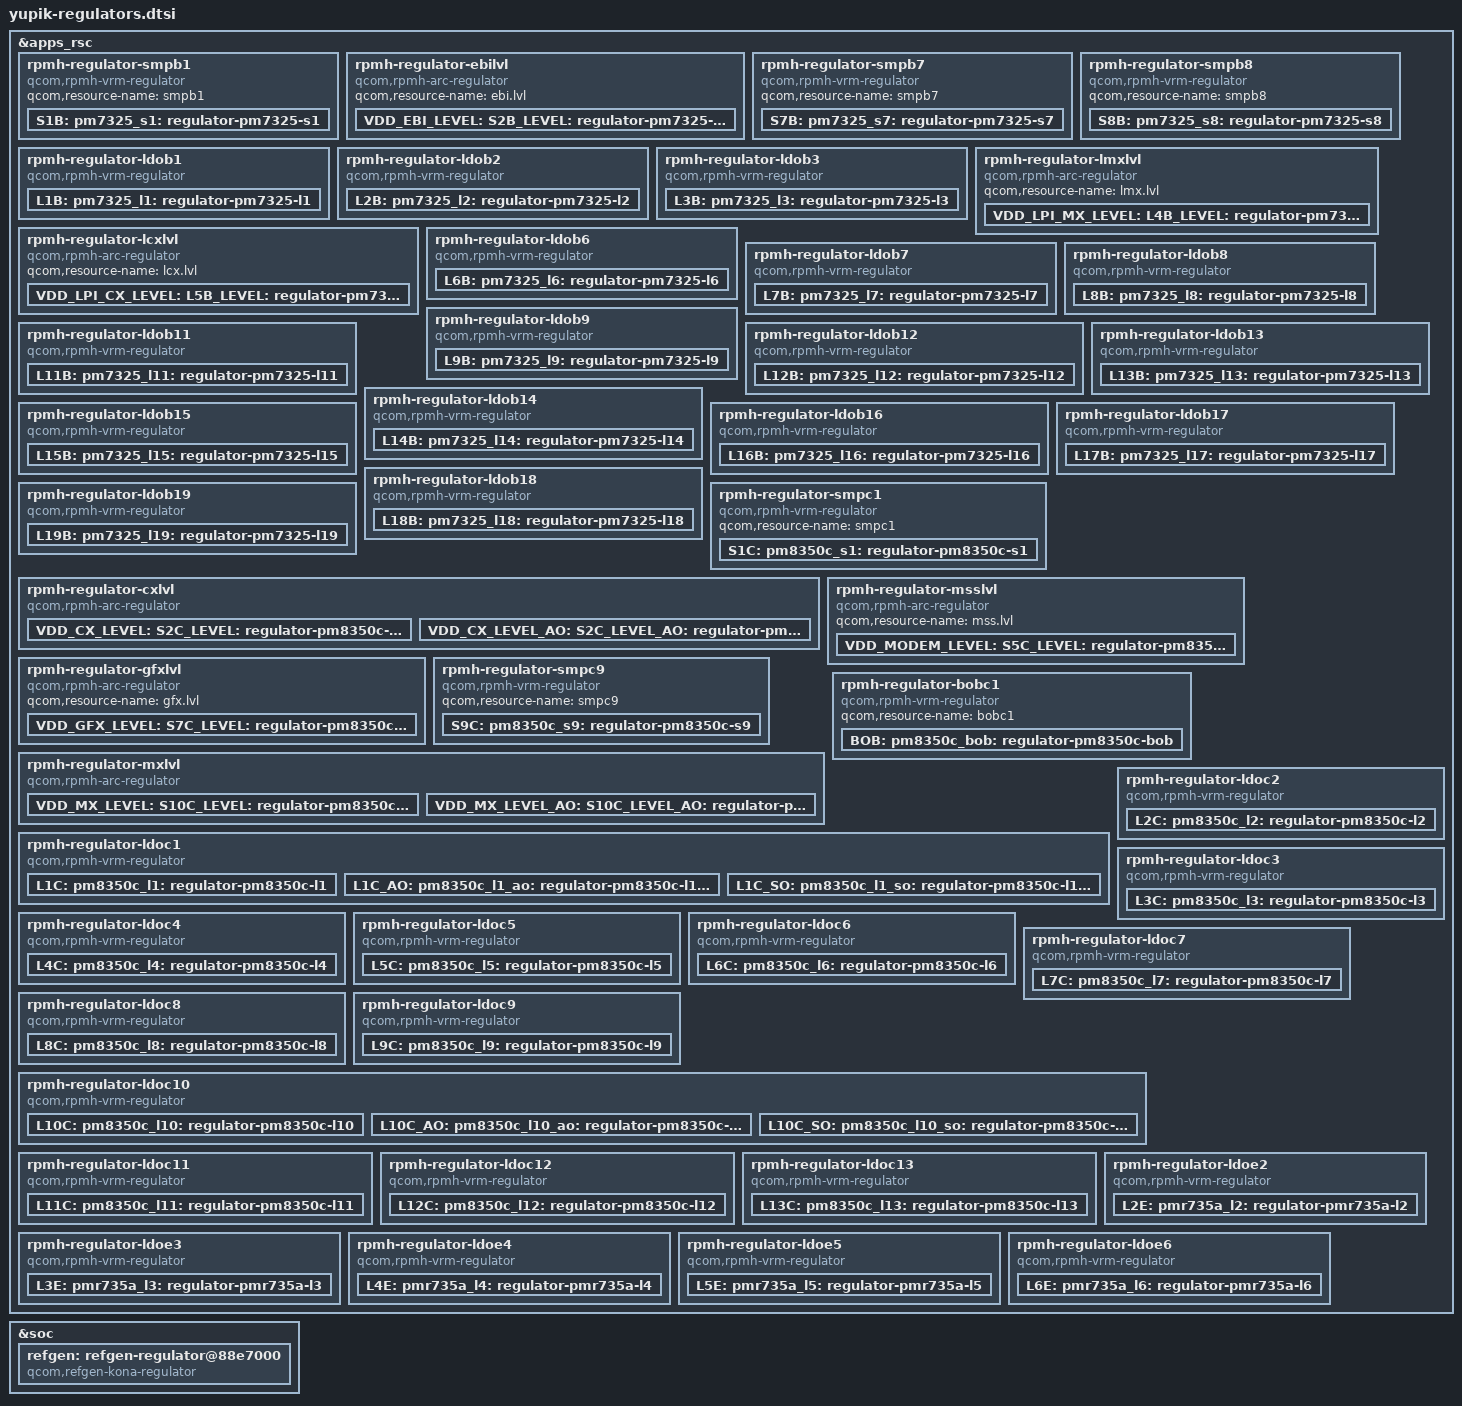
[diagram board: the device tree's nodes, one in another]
#include <dt-bindings/regulator/qcom,rpmh-regulator-levels.h>

&apps_rsc {
	rpmh-regulator-smpb1 {
		compatible = "qcom,rpmh-vrm-regulator";
		qcom,resource-name = "smpb1";
		S1B:
		pm7325_s1: regulator-pm7325-s1 {
			regulator-name = "pm7325_s1";
			qcom,set = <RPMH_REGULATOR_SET_ALL>;
			regulator-min-microvolt = <1840000>;
			regulator-max-microvolt = <2040000>;
			qcom,init-voltage = <1872000>;
		};
	};

	rpmh-regulator-ebilvl {
		compatible = "qcom,rpmh-arc-regulator";
		qcom,resource-name = "ebi.lvl";
		VDD_EBI_LEVEL:
		S2B_LEVEL:
		pm7325_s2_level: regulator-pm7325-s2-level {
			regulator-name = "pm7325_s2_level";
			qcom,set = <RPMH_REGULATOR_SET_ALL>;
			regulator-min-microvolt =
				<RPMH_REGULATOR_LEVEL_RETENTION>;
			regulator-max-microvolt = <RPMH_REGULATOR_LEVEL_MAX>;
			qcom,init-voltage-level =
				<RPMH_REGULATOR_LEVEL_RETENTION>;
		};
	};

	rpmh-regulator-smpb7 {
		compatible = "qcom,rpmh-vrm-regulator";
		qcom,resource-name = "smpb7";
		S7B:
		pm7325_s7: regulator-pm7325-s7 {
			regulator-name = "pm7325_s7";
			qcom,set = <RPMH_REGULATOR_SET_ALL>;
			regulator-min-microvolt = <535000>;
			regulator-max-microvolt = <1120000>;
			qcom,init-voltage = <972000>;
		};
	};

	rpmh-regulator-smpb8 {
		compatible = "qcom,rpmh-vrm-regulator";
		qcom,resource-name = "smpb8";
		S8B:
		pm7325_s8: regulator-pm7325-s8 {
			regulator-name = "pm7325_s8";
			qcom,set = <RPMH_REGULATOR_SET_ALL>;
			regulator-min-microvolt = <1200000>;
			regulator-max-microvolt = <1500000>;
			qcom,init-voltage = <1272000>;
		};
	};

	rpmh-regulator-ldob1 {
		compatible = "qcom,rpmh-vrm-regulator";
		qcom,resource-name = "ldob1";
		qcom,regulator-type = "pmic5-ldo";
		qcom,supported-modes =
			<RPMH_REGULATOR_MODE_LPM
			RPMH_REGULATOR_MODE_HPM>;
		qcom,mode-threshold-currents = <0 30000>;
		L1B:
		pm7325_l1: regulator-pm7325-l1 {
			regulator-name = "pm7325_l1";
			qcom,set = <RPMH_REGULATOR_SET_ALL>;
			regulator-min-microvolt = <825000>;
			regulator-max-microvolt = <925000>;
			qcom,init-voltage = <912000>;
			qcom,init-mode = <RPMH_REGULATOR_MODE_HPM>;
		};
	};

	rpmh-regulator-ldob2 {
		compatible = "qcom,rpmh-vrm-regulator";
		qcom,resource-name = "ldob2";
		qcom,regulator-type = "pmic5-ldo";
		qcom,supported-modes =
			<RPMH_REGULATOR_MODE_LPM
			RPMH_REGULATOR_MODE_HPM>;
		qcom,mode-threshold-currents = <0 30000>;
		L2B:
		pm7325_l2: regulator-pm7325-l2 {
			regulator-name = "pm7325_l2";
			qcom,set = <RPMH_REGULATOR_SET_ALL>;
			regulator-min-microvolt = <2700000>;
			regulator-max-microvolt = <3544000>;
			qcom,init-voltage = <3072000>;
			qcom,init-mode = <RPMH_REGULATOR_MODE_HPM>;
		};
	};

	rpmh-regulator-ldob3 {
		compatible = "qcom,rpmh-vrm-regulator";
		qcom,resource-name = "ldob3";
		qcom,regulator-type = "pmic5-ldo";
		qcom,supported-modes =
			<RPMH_REGULATOR_MODE_LPM
			RPMH_REGULATOR_MODE_HPM>;
		qcom,mode-threshold-currents = <0 30000>;
		L3B:
		pm7325_l3: regulator-pm7325-l3 {
			regulator-name = "pm7325_l3";
			qcom,set = <RPMH_REGULATOR_SET_ALL>;
			regulator-min-microvolt = <312000>;
			regulator-max-microvolt = <910000>;
			qcom,init-voltage = <504000>;
			qcom,init-mode = <RPMH_REGULATOR_MODE_HPM>;
		};
	};

	rpmh-regulator-lmxlvl {
		compatible = "qcom,rpmh-arc-regulator";
		qcom,resource-name = "lmx.lvl";
		VDD_LPI_MX_LEVEL:
		L4B_LEVEL:
		pm7325_l4_level: regulator-pm7325-l4-level {
			regulator-name = "pm7325_l4_level";
			qcom,set = <RPMH_REGULATOR_SET_ALL>;
			regulator-min-microvolt =
				<RPMH_REGULATOR_LEVEL_RETENTION>;
			regulator-max-microvolt = <RPMH_REGULATOR_LEVEL_MAX>;
			qcom,init-voltage-level =
				<RPMH_REGULATOR_LEVEL_RETENTION>;
		};
	};

	rpmh-regulator-lcxlvl {
		compatible = "qcom,rpmh-arc-regulator";
		qcom,resource-name = "lcx.lvl";
		VDD_LPI_CX_LEVEL:
		L5B_LEVEL:
		pm7325_l5_level: regulator-pm7325-l5-level {
			regulator-name = "pm7325_l5_level";
			qcom,set = <RPMH_REGULATOR_SET_ALL>;
			regulator-min-microvolt =
				<RPMH_REGULATOR_LEVEL_RETENTION>;
			regulator-max-microvolt = <RPMH_REGULATOR_LEVEL_MAX>;
			qcom,init-voltage-level =
				<RPMH_REGULATOR_LEVEL_RETENTION>;
		};
	};

	rpmh-regulator-ldob6 {
		compatible = "qcom,rpmh-vrm-regulator";
		qcom,resource-name = "ldob6";
		qcom,regulator-type = "pmic5-ldo";
		qcom,supported-modes =
			<RPMH_REGULATOR_MODE_LPM
			RPMH_REGULATOR_MODE_HPM>;
		qcom,mode-threshold-currents = <0 30000>;
		proxy-supply = <&pm7325_l6>;
		L6B:
		pm7325_l6: regulator-pm7325-l6 {
			regulator-name = "pm7325_l6";
			qcom,set = <RPMH_REGULATOR_SET_ALL>;
			regulator-min-microvolt = <1140000>;
			regulator-max-microvolt = <1260000>;
			qcom,init-voltage = <1200000>;
			qcom,proxy-consumer-enable;
			qcom,proxy-consumer-current = <8350>;
			qcom,init-mode = <RPMH_REGULATOR_MODE_HPM>;
		};
	};

	rpmh-regulator-ldob7 {
		compatible = "qcom,rpmh-vrm-regulator";
		qcom,resource-name = "ldob7";
		qcom,regulator-type = "pmic5-ldo";
		qcom,supported-modes =
			<RPMH_REGULATOR_MODE_LPM
			RPMH_REGULATOR_MODE_HPM>;
		qcom,mode-threshold-currents = <0 30000>;
		L7B:
		pm7325_l7: regulator-pm7325-l7 {
			regulator-name = "pm7325_l7";
			qcom,set = <RPMH_REGULATOR_SET_ALL>;
			regulator-min-microvolt = <2400000>;
			regulator-max-microvolt = <3544000>;
			qcom,init-voltage = <2952000>;
			qcom,init-mode = <RPMH_REGULATOR_MODE_HPM>;
		};
	};

	rpmh-regulator-ldob8 {
		compatible = "qcom,rpmh-vrm-regulator";
		qcom,resource-name = "ldob8";
		qcom,regulator-type = "pmic5-ldo";
		qcom,supported-modes =
			<RPMH_REGULATOR_MODE_LPM
			RPMH_REGULATOR_MODE_HPM>;
		qcom,mode-threshold-currents = <0 30000>;
		L8B:
		pm7325_l8: regulator-pm7325-l8 {
			regulator-name = "pm7325_l8";
			qcom,set = <RPMH_REGULATOR_SET_ALL>;
			regulator-min-microvolt = <870000>;
			regulator-max-microvolt = <970000>;
			qcom,init-voltage = <904000>;
			qcom,init-mode = <RPMH_REGULATOR_MODE_HPM>;
		};
	};

	rpmh-regulator-ldob9 {
		compatible = "qcom,rpmh-vrm-regulator";
		qcom,resource-name = "ldob9";
		qcom,regulator-type = "pmic5-ldo";
		qcom,supported-modes =
			<RPMH_REGULATOR_MODE_LPM
			RPMH_REGULATOR_MODE_HPM>;
		qcom,mode-threshold-currents = <0 30000>;
		L9B:
		pm7325_l9: regulator-pm7325-l9 {
			regulator-name = "pm7325_l9";
			qcom,set = <RPMH_REGULATOR_SET_ALL>;
			regulator-min-microvolt = <1080000>;
			regulator-max-microvolt = <1304000>;
			qcom,init-voltage = <1200000>;
			qcom,init-mode = <RPMH_REGULATOR_MODE_HPM>;
		};
	};

	rpmh-regulator-ldob11 {
		compatible = "qcom,rpmh-vrm-regulator";
		qcom,resource-name = "ldob11";
		qcom,regulator-type = "pmic5-ldo";
		qcom,supported-modes =
			<RPMH_REGULATOR_MODE_LPM
			RPMH_REGULATOR_MODE_HPM>;
		qcom,mode-threshold-currents = <0 30000>;
		L11B:
		pm7325_l11: regulator-pm7325-l11 {
			regulator-name = "pm7325_l11";
			qcom,set = <RPMH_REGULATOR_SET_ALL>;
			regulator-min-microvolt = <1504000>;
			regulator-max-microvolt = <2000000>;
			qcom,init-voltage = <1504000>;
			qcom,init-mode = <RPMH_REGULATOR_MODE_HPM>;
		};
	};

	rpmh-regulator-ldob12 {
		compatible = "qcom,rpmh-vrm-regulator";
		qcom,resource-name = "ldob12";
		qcom,regulator-type = "pmic5-ldo";
		qcom,supported-modes =
			<RPMH_REGULATOR_MODE_LPM
			RPMH_REGULATOR_MODE_HPM>;
		qcom,mode-threshold-currents = <0 30000>;
		L12B:
		pm7325_l12: regulator-pm7325-l12 {
			regulator-name = "pm7325_l12";
			qcom,set = <RPMH_REGULATOR_SET_ALL>;
			regulator-min-microvolt = <751000>;
			regulator-max-microvolt = <824000>;
			qcom,init-voltage = <751000>;
			qcom,init-mode = <RPMH_REGULATOR_MODE_HPM>;
		};
	};

	rpmh-regulator-ldob13 {
		compatible = "qcom,rpmh-vrm-regulator";
		qcom,resource-name = "ldob13";
		qcom,regulator-type = "pmic5-ldo";
		qcom,supported-modes =
			<RPMH_REGULATOR_MODE_LPM
			RPMH_REGULATOR_MODE_HPM>;
		qcom,mode-threshold-currents = <0 30000>;
		L13B:
		pm7325_l13: regulator-pm7325-l13 {
			regulator-name = "pm7325_l13";
			qcom,set = <RPMH_REGULATOR_SET_ALL>;
			regulator-min-microvolt = <530000>;
			regulator-max-microvolt = <824000>;
			qcom,init-voltage = <530000>;
			qcom,init-mode = <RPMH_REGULATOR_MODE_HPM>;
		};
	};

	rpmh-regulator-ldob14 {
		compatible = "qcom,rpmh-vrm-regulator";
		qcom,resource-name = "ldob14";
		qcom,regulator-type = "pmic5-ldo";
		qcom,supported-modes =
			<RPMH_REGULATOR_MODE_LPM
			RPMH_REGULATOR_MODE_HPM>;
		qcom,mode-threshold-currents = <0 30000>;
		L14B:
		pm7325_l14: regulator-pm7325-l14 {
			regulator-name = "pm7325_l14";
			qcom,set = <RPMH_REGULATOR_SET_ALL>;
			regulator-min-microvolt = <1080000>;
			regulator-max-microvolt = <1304000>;
			qcom,init-voltage = <1080000>;
			qcom,init-mode = <RPMH_REGULATOR_MODE_HPM>;
		};
	};

	rpmh-regulator-ldob15 {
		compatible = "qcom,rpmh-vrm-regulator";
		qcom,resource-name = "ldob15";
		qcom,regulator-type = "pmic5-ldo";
		qcom,supported-modes =
			<RPMH_REGULATOR_MODE_LPM
			RPMH_REGULATOR_MODE_HPM>;
		qcom,mode-threshold-currents = <0 30000>;
		L15B:
		pm7325_l15: regulator-pm7325-l15 {
			regulator-name = "pm7325_l15";
			qcom,set = <RPMH_REGULATOR_SET_ALL>;
			regulator-min-microvolt = <765000>;
			regulator-max-microvolt = <1020000>;
			qcom,init-voltage = <765000>;
			qcom,init-mode = <RPMH_REGULATOR_MODE_HPM>;
		};
	};

	rpmh-regulator-ldob16 {
		compatible = "qcom,rpmh-vrm-regulator";
		qcom,resource-name = "ldob16";
		qcom,regulator-type = "pmic5-ldo";
		qcom,supported-modes =
			<RPMH_REGULATOR_MODE_LPM
			RPMH_REGULATOR_MODE_HPM>;
		qcom,mode-threshold-currents = <0 30000>;
		L16B:
		pm7325_l16: regulator-pm7325-l16 {
			regulator-name = "pm7325_l16";
			qcom,set = <RPMH_REGULATOR_SET_ALL>;
			regulator-min-microvolt = <1100000>;
			regulator-max-microvolt = <1300000>;
			qcom,init-voltage = <1100000>;
			qcom,init-mode = <RPMH_REGULATOR_MODE_HPM>;
		};
	};

	rpmh-regulator-ldob17 {
		compatible = "qcom,rpmh-vrm-regulator";
		qcom,resource-name = "ldob17";
		qcom,regulator-type = "pmic5-ldo";
		qcom,supported-modes =
			<RPMH_REGULATOR_MODE_LPM
			RPMH_REGULATOR_MODE_HPM>;
		qcom,mode-threshold-currents = <0 30000>;
		L17B:
		pm7325_l17: regulator-pm7325-l17 {
			regulator-name = "pm7325_l17";
			qcom,set = <RPMH_REGULATOR_SET_ALL>;
			regulator-min-microvolt = <1700000>;
			regulator-max-microvolt = <1900000>;
			qcom,init-voltage = <1700000>;
			qcom,init-mode = <RPMH_REGULATOR_MODE_HPM>;
		};
	};

	rpmh-regulator-ldob18 {
		compatible = "qcom,rpmh-vrm-regulator";
		qcom,resource-name = "ldob18";
		qcom,regulator-type = "pmic5-ldo";
		qcom,supported-modes =
			<RPMH_REGULATOR_MODE_LPM
			RPMH_REGULATOR_MODE_HPM>;
		qcom,mode-threshold-currents = <0 30000>;
		L18B:
		pm7325_l18: regulator-pm7325-l18 {
			regulator-name = "pm7325_l18";
			qcom,set = <RPMH_REGULATOR_SET_ALL>;
			regulator-min-microvolt = <1800000>;
			regulator-max-microvolt = <2000000>;
			qcom,init-voltage = <1800000>;
			qcom,init-mode = <RPMH_REGULATOR_MODE_HPM>;
		};
	};

	rpmh-regulator-ldob19 {
		compatible = "qcom,rpmh-vrm-regulator";
		qcom,resource-name = "ldob19";
		qcom,regulator-type = "pmic5-ldo";
		qcom,supported-modes =
			<RPMH_REGULATOR_MODE_LPM
			RPMH_REGULATOR_MODE_HPM>;
		qcom,mode-threshold-currents = <0 30000>;
		L19B:
		pm7325_l19: regulator-pm7325-l19 {
			regulator-name = "pm7325_l19";
			qcom,set = <RPMH_REGULATOR_SET_ALL>;
			regulator-min-microvolt = <1800000>;
			regulator-max-microvolt = <2000000>;
			qcom,init-voltage = <1800000>;
			qcom,init-mode = <RPMH_REGULATOR_MODE_HPM>;
		};
	};

	rpmh-regulator-smpc1 {
		compatible = "qcom,rpmh-vrm-regulator";
		qcom,resource-name = "smpc1";
		S1C:
		pm8350c_s1: regulator-pm8350c-s1 {
			regulator-name = "pm8350c_s1";
			qcom,set = <RPMH_REGULATOR_SET_ALL>;
			regulator-min-microvolt = <2190000>;
			regulator-max-microvolt = <2210000>;
			qcom,init-voltage = <2190000>;
		};
	};

	rpmh-regulator-cxlvl {
		compatible = "qcom,rpmh-arc-regulator";
		qcom,resource-name = "cx.lvl";
		proxy-supply = <&VDD_CX_LEVEL>;
		VDD_CX_LEVEL:
		S2C_LEVEL:
		pm8350c_s2_level: regulator-pm8350c-s2-level {
			regulator-name = "pm8350c_s2_level";
			qcom,set = <RPMH_REGULATOR_SET_ALL>;
			regulator-min-microvolt =
				<RPMH_REGULATOR_LEVEL_RETENTION>;
			regulator-max-microvolt = <RPMH_REGULATOR_LEVEL_MAX>;
			qcom,init-voltage-level =
				<RPMH_REGULATOR_LEVEL_TURBO>;
			qcom,min-dropout-voltage-level = <(-1)>;
			qcom,proxy-consumer-enable;
			qcom,proxy-consumer-voltage =
				<RPMH_REGULATOR_LEVEL_TURBO
				 RPMH_REGULATOR_LEVEL_MAX>;
		};

		VDD_CX_LEVEL_AO:
		S2C_LEVEL_AO:
		pm8350c_s2_level_ao: regulator-pm8350c-s2-level-ao {
			regulator-name = "pm8350c_s2_level_ao";
			qcom,set = <RPMH_REGULATOR_SET_ACTIVE>;
			regulator-min-microvolt =
				<RPMH_REGULATOR_LEVEL_RETENTION>;
			regulator-max-microvolt = <RPMH_REGULATOR_LEVEL_MAX>;
			qcom,init-voltage-level =
				<RPMH_REGULATOR_LEVEL_RETENTION>;
			qcom,min-dropout-voltage-level = <(-1)>;
		};
	};

	rpmh-regulator-msslvl {
		compatible = "qcom,rpmh-arc-regulator";
		qcom,resource-name = "mss.lvl";
		VDD_MODEM_LEVEL:
		S5C_LEVEL:
		pm8350c_s5_level: regulator-pm8350c-s5-level {
			regulator-name = "pm8350c_s5_level";
			qcom,set = <RPMH_REGULATOR_SET_ALL>;
			regulator-min-microvolt =
				<RPMH_REGULATOR_LEVEL_RETENTION>;
			regulator-max-microvolt = <RPMH_REGULATOR_LEVEL_MAX>;
			qcom,init-voltage-level =
				<RPMH_REGULATOR_LEVEL_RETENTION>;
		};
	};

	rpmh-regulator-gfxlvl {
		compatible = "qcom,rpmh-arc-regulator";
		qcom,resource-name = "gfx.lvl";
		VDD_GFX_LEVEL:
		S7C_LEVEL:
		pm8350c_s7_level: regulator-pm8350c-s7-level {
			regulator-name = "pm8350c_s7_level";
			qcom,set = <RPMH_REGULATOR_SET_ALL>;
			regulator-min-microvolt =
				<RPMH_REGULATOR_LEVEL_RETENTION>;
			regulator-max-microvolt = <RPMH_REGULATOR_LEVEL_MAX>;
			qcom,init-voltage-level =
				<RPMH_REGULATOR_LEVEL_RETENTION>;
		};
	};

	rpmh-regulator-smpc9 {
		compatible = "qcom,rpmh-vrm-regulator";
		qcom,resource-name = "smpc9";
		S9C:
		pm8350c_s9: regulator-pm8350c-s9 {
			regulator-name = "pm8350c_s9";
			qcom,set = <RPMH_REGULATOR_SET_ALL>;
			regulator-min-microvolt = <1010000>;
			regulator-max-microvolt = <1170000>;
			qcom,init-voltage = <1084000>;
		};
	};

	rpmh-regulator-mxlvl {
		compatible = "qcom,rpmh-arc-regulator";
		qcom,resource-name = "mx.lvl";
		proxy-supply = <&VDD_MX_LEVEL>;
		VDD_MX_LEVEL:
		S10C_LEVEL:
		pm8350c_s10_level: regulator-pm8350c-s10-level {
			regulator-name = "pm8350c_s10_level";
			qcom,set = <RPMH_REGULATOR_SET_ALL>;
			regulator-min-microvolt =
				<RPMH_REGULATOR_LEVEL_RETENTION>;
			regulator-max-microvolt = <RPMH_REGULATOR_LEVEL_MAX>;
			qcom,init-voltage-level =
				<RPMH_REGULATOR_LEVEL_TURBO>;
			qcom,min-dropout-voltage-level = <(-1)>;
			qcom,proxy-consumer-enable;
			qcom,proxy-consumer-voltage =
				<RPMH_REGULATOR_LEVEL_TURBO
				 RPMH_REGULATOR_LEVEL_MAX>;
		};

		VDD_MX_LEVEL_AO:
		S10C_LEVEL_AO:
		pm8350c_s10_level_ao: regulator-pm8350c-s10-level-ao {
			regulator-name = "pm8350c_s10_level_ao";
			qcom,set = <RPMH_REGULATOR_SET_ACTIVE>;
			regulator-min-microvolt =
				<RPMH_REGULATOR_LEVEL_RETENTION>;
			regulator-max-microvolt = <RPMH_REGULATOR_LEVEL_MAX>;
			qcom,init-voltage-level =
				<RPMH_REGULATOR_LEVEL_RETENTION>;
			qcom,min-dropout-voltage-level = <(-1)>;
		};
	};

	rpmh-regulator-bobc1 {
		compatible = "qcom,rpmh-vrm-regulator";
		qcom,resource-name = "bobc1";
		BOB: pm8350c_bob: regulator-pm8350c-bob {
			regulator-name = "pm8350c_bob";
			qcom,set = <RPMH_REGULATOR_SET_ALL>;
			regulator-min-microvolt = <3008000>;
			regulator-max-microvolt = <3960000>;
			qcom,init-voltage = <3296000>;
		};
	};

	rpmh-regulator-ldoc1 {
		compatible = "qcom,rpmh-vrm-regulator";
		qcom,resource-name = "ldoc1";
		qcom,regulator-type = "pmic5-ldo";
		qcom,supported-modes =
			<RPMH_REGULATOR_MODE_LPM
			RPMH_REGULATOR_MODE_HPM>;
		qcom,mode-threshold-currents = <0 30000>;
		L1C:
		pm8350c_l1: regulator-pm8350c-l1 {
			regulator-name = "pm8350c_l1";
			qcom,set = <RPMH_REGULATOR_SET_ALL>;
			regulator-min-microvolt = <1800000>;
			regulator-max-microvolt = <1980000>;
			qcom,init-voltage = <1800000>;
			qcom,init-mode = <RPMH_REGULATOR_MODE_HPM>;
		};

		L1C_AO: pm8350c_l1_ao: regulator-pm8350c-l1-ao {
			regulator-name = "pm8350c_l1_ao";
			qcom,set = <RPMH_REGULATOR_SET_ACTIVE>;
			regulator-min-microvolt = <1800000>;
			regulator-max-microvolt = <1980000>;
			qcom,init-voltage = <1800000>;
			qcom,init-mode = <RPMH_REGULATOR_MODE_LPM>;
		};

		L1C_SO: pm8350c_l1_so: regulator-pm8350c-l1-so {
			regulator-name = "pm8350c_l1_so";
			qcom,set = <RPMH_REGULATOR_SET_SLEEP>;
			regulator-min-microvolt = <1800000>;
			regulator-max-microvolt = <1980000>;
			qcom,init-voltage = <1800000>;
			qcom,init-mode = <RPMH_REGULATOR_MODE_LPM>;
			qcom,init-enable = <0>;
		};
	};

	rpmh-regulator-ldoc2 {
		compatible = "qcom,rpmh-vrm-regulator";
		qcom,resource-name = "ldoc2";
		qcom,regulator-type = "pmic5-ldo";
		qcom,supported-modes =
			<RPMH_REGULATOR_MODE_LPM
			RPMH_REGULATOR_MODE_HPM>;
		qcom,mode-threshold-currents = <0 30000>;
		L2C:
		pm8350c_l2: regulator-pm8350c-l2 {
			regulator-name = "pm8350c_l2";
			qcom,set = <RPMH_REGULATOR_SET_ALL>;
			regulator-min-microvolt = <1620000>;
			regulator-max-microvolt = <1980000>;
			qcom,init-voltage = <1620000>;
			qcom,init-mode = <RPMH_REGULATOR_MODE_HPM>;
		};
	};

	rpmh-regulator-ldoc3 {
		compatible = "qcom,rpmh-vrm-regulator";
		qcom,resource-name = "ldoc3";
		qcom,regulator-type = "pmic5-ldo";
		qcom,supported-modes =
			<RPMH_REGULATOR_MODE_LPM
			RPMH_REGULATOR_MODE_HPM>;
		qcom,mode-threshold-currents = <0 30000>;
		L3C:
		pm8350c_l3: regulator-pm8350c-l3 {
			regulator-name = "pm8350c_l3";
			qcom,set = <RPMH_REGULATOR_SET_ALL>;
			regulator-min-microvolt = <2800000>;
			regulator-max-microvolt = <3540000>;
			qcom,init-voltage = <2800000>;
			qcom,init-mode = <RPMH_REGULATOR_MODE_HPM>;
		};
	};

	rpmh-regulator-ldoc4 {
		compatible = "qcom,rpmh-vrm-regulator";
		qcom,resource-name = "ldoc4";
		qcom,regulator-type = "pmic5-ldo";
		qcom,supported-modes =
			<RPMH_REGULATOR_MODE_LPM
			RPMH_REGULATOR_MODE_HPM>;
		qcom,mode-threshold-currents = <0 30000>;
		L4C:
		pm8350c_l4: regulator-pm8350c-l4 {
			regulator-name = "pm8350c_l4";
			qcom,set = <RPMH_REGULATOR_SET_ALL>;
			regulator-min-microvolt = <1620000>;
			regulator-max-microvolt = <3300000>;
			qcom,init-voltage = <1620000>;
			qcom,init-mode = <RPMH_REGULATOR_MODE_HPM>;
		};
	};

	rpmh-regulator-ldoc5 {
		compatible = "qcom,rpmh-vrm-regulator";
		qcom,resource-name = "ldoc5";
		qcom,regulator-type = "pmic5-ldo";
		qcom,supported-modes =
			<RPMH_REGULATOR_MODE_LPM
			RPMH_REGULATOR_MODE_HPM>;
		qcom,mode-threshold-currents = <0 30000>;
		L5C:
		pm8350c_l5: regulator-pm8350c-l5 {
			regulator-name = "pm8350c_l5";
			qcom,set = <RPMH_REGULATOR_SET_ALL>;
			regulator-min-microvolt = <1620000>;
			regulator-max-microvolt = <3300000>;
			qcom,init-voltage = <1620000>;
			qcom,init-mode = <RPMH_REGULATOR_MODE_HPM>;
		};
	};

	rpmh-regulator-ldoc6 {
		compatible = "qcom,rpmh-vrm-regulator";
		qcom,resource-name = "ldoc6";
		qcom,regulator-type = "pmic5-ldo";
		qcom,supported-modes =
			<RPMH_REGULATOR_MODE_LPM
			RPMH_REGULATOR_MODE_HPM>;
		qcom,mode-threshold-currents = <0 30000>;
		L6C:
		pm8350c_l6: regulator-pm8350c-l6 {
			regulator-name = "pm8350c_l6";
			qcom,set = <RPMH_REGULATOR_SET_ALL>;
			regulator-min-microvolt = <1650000>;
			regulator-max-microvolt = <3544000>;
			qcom,init-voltage = <2960000>;
			qcom,init-mode = <RPMH_REGULATOR_MODE_HPM>;
		};
	};

	rpmh-regulator-ldoc7 {
		compatible = "qcom,rpmh-vrm-regulator";
		qcom,resource-name = "ldoc7";
		qcom,regulator-type = "pmic5-ldo";
		qcom,supported-modes =
			<RPMH_REGULATOR_MODE_LPM
			RPMH_REGULATOR_MODE_HPM>;
		qcom,mode-threshold-currents = <0 30000>;
		L7C:
		pm8350c_l7: regulator-pm8350c-l7 {
			regulator-name = "pm8350c_l7";
			qcom,set = <RPMH_REGULATOR_SET_ALL>;
			regulator-min-microvolt = <3000000>;
			regulator-max-microvolt = <3544000>;
			qcom,init-voltage = <3000000>;
			qcom,init-mode = <RPMH_REGULATOR_MODE_HPM>;
		};
	};

	rpmh-regulator-ldoc8 {
		compatible = "qcom,rpmh-vrm-regulator";
		qcom,resource-name = "ldoc8";
		qcom,regulator-type = "pmic5-ldo";
		qcom,supported-modes =
			<RPMH_REGULATOR_MODE_LPM
			RPMH_REGULATOR_MODE_HPM>;
		qcom,mode-threshold-currents = <0 30000>;
		L8C:
		pm8350c_l8: regulator-pm8350c-l8 {
			regulator-name = "pm8350c_l8";
			qcom,set = <RPMH_REGULATOR_SET_ALL>;
			regulator-min-microvolt = <1620000>;
			regulator-max-microvolt = <2000000>;
			qcom,init-voltage = <1620000>;
			qcom,init-mode = <RPMH_REGULATOR_MODE_HPM>;
		};
	};

	rpmh-regulator-ldoc9 {
		compatible = "qcom,rpmh-vrm-regulator";
		qcom,resource-name = "ldoc9";
		qcom,regulator-type = "pmic5-ldo";
		qcom,supported-modes =
			<RPMH_REGULATOR_MODE_LPM
			RPMH_REGULATOR_MODE_HPM>;
		qcom,mode-threshold-currents = <0 30000>;
		L9C:
		pm8350c_l9: regulator-pm8350c-l9 {
			regulator-name = "pm8350c_l9";
			qcom,set = <RPMH_REGULATOR_SET_ALL>;
			regulator-min-microvolt = <2700000>;
			regulator-max-microvolt = <3544000>;
			qcom,init-voltage = <2960000>;
			qcom,init-mode = <RPMH_REGULATOR_MODE_HPM>;
		};
	};

	rpmh-regulator-ldoc10 {
		compatible = "qcom,rpmh-vrm-regulator";
		qcom,resource-name = "ldoc10";
		qcom,regulator-type = "pmic5-ldo";
		qcom,supported-modes =
			<RPMH_REGULATOR_MODE_LPM
			RPMH_REGULATOR_MODE_HPM>;
		qcom,mode-threshold-currents = <0 30000>;
		proxy-supply = <&pm8350c_l10>;
		L10C:
		pm8350c_l10: regulator-pm8350c-l10 {
			regulator-name = "pm8350c_l10";
			qcom,set = <RPMH_REGULATOR_SET_ALL>;
			regulator-min-microvolt = <720000>;
			regulator-max-microvolt = <1050000>;
			qcom,init-voltage = <880000>;
			qcom,proxy-consumer-enable;
			qcom,proxy-consumer-current = <37550>;
			qcom,init-mode = <RPMH_REGULATOR_MODE_HPM>;
		};

		L10C_AO:
		pm8350c_l10_ao: regulator-pm8350c-l10-ao {
			regulator-name = "pm8350c_l10_ao";
			qcom,set = <RPMH_REGULATOR_SET_ACTIVE>;
			regulator-min-microvolt = <720000>;
			regulator-max-microvolt = <1050000>;
			qcom,init-voltage = <880000>;
			qcom,init-mode = <RPMH_REGULATOR_MODE_LPM>;
		};

		L10C_SO:
		pm8350c_l10_so: regulator-pm8350c-l10-so {
			regulator-name = "pm8350c_l10_so";
			qcom,set = <RPMH_REGULATOR_SET_SLEEP>;
			regulator-min-microvolt = <720000>;
			regulator-max-microvolt = <1050000>;
			qcom,init-voltage = <880000>;
			qcom,init-mode = <RPMH_REGULATOR_MODE_LPM>;
			qcom,init-enable = <0>;
		};
	};

	rpmh-regulator-ldoc11 {
		compatible = "qcom,rpmh-vrm-regulator";
		qcom,resource-name = "ldoc11";
		qcom,regulator-type = "pmic5-ldo";
		qcom,supported-modes =
			<RPMH_REGULATOR_MODE_LPM
			RPMH_REGULATOR_MODE_HPM>;
		qcom,mode-threshold-currents = <0 30000>;
		L11C:
		pm8350c_l11: regulator-pm8350c-l11 {
			regulator-name = "pm8350c_l11";
			qcom,set = <RPMH_REGULATOR_SET_ALL>;
			regulator-min-microvolt = <2800000>;
			regulator-max-microvolt = <3544000>;
			qcom,init-voltage = <2800000>;
			qcom,init-mode = <RPMH_REGULATOR_MODE_HPM>;
		};
	};

	rpmh-regulator-ldoc12 {
		compatible = "qcom,rpmh-vrm-regulator";
		qcom,resource-name = "ldoc12";
		qcom,regulator-type = "pmic5-ldo";
		qcom,supported-modes =
			<RPMH_REGULATOR_MODE_LPM
			RPMH_REGULATOR_MODE_HPM>;
		qcom,mode-threshold-currents = <0 30000>;
		L12C:
		pm8350c_l12: regulator-pm8350c-l12 {
			regulator-name = "pm8350c_l12";
			qcom,set = <RPMH_REGULATOR_SET_ALL>;
			regulator-min-microvolt = <1650000>;
			regulator-max-microvolt = <2000000>;
			qcom,init-voltage = <1650000>;
			qcom,init-mode = <RPMH_REGULATOR_MODE_HPM>;
		};
	};

	rpmh-regulator-ldoc13 {
		compatible = "qcom,rpmh-vrm-regulator";
		qcom,resource-name = "ldoc13";
		qcom,regulator-type = "pmic5-ldo";
		qcom,supported-modes =
			<RPMH_REGULATOR_MODE_LPM
			RPMH_REGULATOR_MODE_HPM>;
		qcom,mode-threshold-currents = <0 30000>;
		L13C:
		pm8350c_l13: regulator-pm8350c-l13 {
			regulator-name = "pm8350c_l13";
			qcom,set = <RPMH_REGULATOR_SET_ALL>;
			regulator-min-microvolt = <2700000>;
			regulator-max-microvolt = <3544000>;
			qcom,init-voltage = <2700000>;
			qcom,init-mode = <RPMH_REGULATOR_MODE_HPM>;
		};
	};

	rpmh-regulator-ldoe2 {
		compatible = "qcom,rpmh-vrm-regulator";
		qcom,resource-name = "ldoe2";
		qcom,regulator-type = "pmic5-ldo";
		qcom,supported-modes =
			<RPMH_REGULATOR_MODE_LPM
			RPMH_REGULATOR_MODE_HPM>;
		qcom,mode-threshold-currents = <0 30000>;
		L2E:
		pmr735a_l2: regulator-pmr735a-l2 {
			regulator-name = "pmr735a_l2";
			qcom,set = <RPMH_REGULATOR_SET_ALL>;
			regulator-min-microvolt = <1200000>;
			regulator-max-microvolt = <1200000>;
			qcom,init-voltage = <1200000>;
			qcom,init-mode = <RPMH_REGULATOR_MODE_HPM>;
		};
	};

	rpmh-regulator-ldoe3 {
		compatible = "qcom,rpmh-vrm-regulator";
		qcom,resource-name = "ldoe3";
		qcom,regulator-type = "pmic5-ldo";
		qcom,supported-modes =
			<RPMH_REGULATOR_MODE_LPM
			RPMH_REGULATOR_MODE_HPM>;
		qcom,mode-threshold-currents = <0 30000>;
		L3E:
		pmr735a_l3: regulator-pmr735a-l3 {
			regulator-name = "pmr735a_l3";
			qcom,set = <RPMH_REGULATOR_SET_ALL>;
			regulator-min-microvolt = <912000>;
			regulator-max-microvolt = <1020000>;
			qcom,init-voltage = <912000>;
			qcom,init-mode = <RPMH_REGULATOR_MODE_HPM>;
		};
	};

	rpmh-regulator-ldoe4 {
		compatible = "qcom,rpmh-vrm-regulator";
		qcom,resource-name = "ldoe4";
		qcom,regulator-type = "pmic5-ldo";
		qcom,supported-modes =
			<RPMH_REGULATOR_MODE_LPM
			RPMH_REGULATOR_MODE_HPM>;
		qcom,mode-threshold-currents = <0 30000>;
		L4E:
		pmr735a_l4: regulator-pmr735a-l4 {
			regulator-name = "pmr735a_l4";
			qcom,set = <RPMH_REGULATOR_SET_ALL>;
			regulator-min-microvolt = <1776000>;
			regulator-max-microvolt = <1890000>;
			qcom,init-voltage = <1776000>;
			qcom,init-mode = <RPMH_REGULATOR_MODE_HPM>;
		};
	};

	rpmh-regulator-ldoe5 {
		compatible = "qcom,rpmh-vrm-regulator";
		qcom,resource-name = "ldoe5";
		qcom,regulator-type = "pmic5-ldo";
		qcom,supported-modes =
			<RPMH_REGULATOR_MODE_LPM
			RPMH_REGULATOR_MODE_HPM>;
		qcom,mode-threshold-currents = <0 30000>;
		L5E:
		pmr735a_l5: regulator-pmr735a-l5 {
			regulator-name = "pmr735a_l5";
			qcom,set = <RPMH_REGULATOR_SET_ALL>;
			regulator-min-microvolt = <800000>;
			regulator-max-microvolt = <800000>;
			qcom,init-voltage = <800000>;
			qcom,init-mode = <RPMH_REGULATOR_MODE_HPM>;
		};
	};

	rpmh-regulator-ldoe6 {
		compatible = "qcom,rpmh-vrm-regulator";
		qcom,resource-name = "ldoe6";
		qcom,regulator-type = "pmic5-ldo";
		qcom,supported-modes =
			<RPMH_REGULATOR_MODE_LPM
			RPMH_REGULATOR_MODE_HPM>;
		qcom,mode-threshold-currents = <0 30000>;
		L6E:
		pmr735a_l6: regulator-pmr735a-l6 {
			regulator-name = "pmr735a_l6";
			qcom,set = <RPMH_REGULATOR_SET_ALL>;
			regulator-min-microvolt = <480000>;
			regulator-max-microvolt = <904000>;
			qcom,init-voltage = <480000>;
			qcom,init-mode = <RPMH_REGULATOR_MODE_HPM>;
		};
	};
};

&soc {
	refgen: refgen-regulator@88e7000 {
		compatible = "qcom,refgen-kona-regulator";
		reg = <0x88e7000 0x84>;
		regulator-name = "refgen";
		proxy-supply = <&refgen>;
		qcom,proxy-consumer-enable;
		regulator-enable-ramp-delay = <5>;
	};
};
